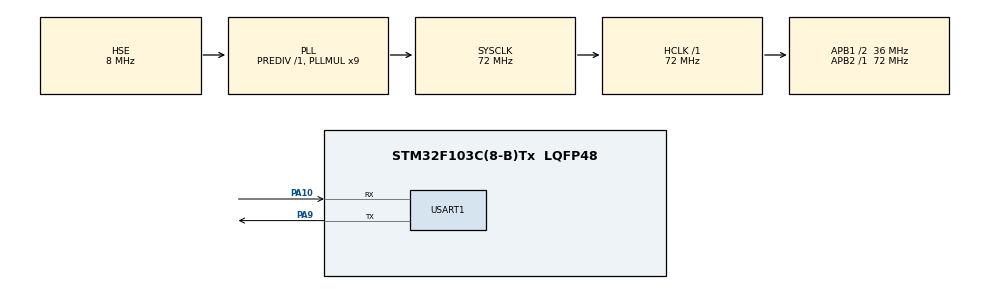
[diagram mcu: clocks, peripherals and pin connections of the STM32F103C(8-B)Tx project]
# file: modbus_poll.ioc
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FREERTOS.INCLUDE_xEventGroupSetBitFromISR=1
FREERTOS.INCLUDE_xTimerPendFunctionCall=1
FREERTOS.Tasks01=defaultTask,0,128,StartDefaultTask,Default,NULL
FREERTOS.configCHECK_FOR_STACK_OVERFLOW=2
FREERTOS.configTIMER_TASK_PRIORITY=3
FREERTOS.configTOTAL_HEAP_SIZE=10240
FREERTOS.configUSE_MALLOC_FAILED_HOOK=1
FREERTOS.configUSE_TIMERS=1
Mcu.Family=STM32F1
Mcu.Name=STM32F103C(8-B)Tx
Mcu.Package=LQFP48
NVIC.PriorityGroup=NVIC_PRIORITYGROUP_4
NVIC.USART1_IRQn=true\:5\:0\:false\:false\:true\:true\:true
PA10.Mode=Asynchronous
PA10.Signal=USART1_RX
PA13.Mode=Serial_Wire
PA13.Signal=SYS_JTMS-SWDIO
PA14.Mode=Serial_Wire
PA14.Signal=SYS_JTCK-SWCLK
PA9.Mode=Asynchronous
PA9.Signal=USART1_TX
PD0-OSC_IN.Mode=HSE-External-Oscillator
PD0-OSC_IN.Signal=RCC_OSC_IN
PD1-OSC_OUT.Mode=HSE-External-Oscillator
PD1-OSC_OUT.Signal=RCC_OSC_OUT
ProjectManager.HeapSize=0x00
ProjectManager.StackSize=0x200
ProjectManager.TargetToolchain=EWARM
RCC.AHBFreq_Value=72000000
RCC.APB1CLKDivider=RCC_HCLK_DIV2
RCC.APB1Freq_Value=36000000
RCC.APB1TimFreq_Value=72000000
RCC.APB2Freq_Value=72000000
RCC.APB2TimFreq_Value=72000000
RCC.HCLKFreq_Value=72000000
RCC.PLLMUL=RCC_PLL_MUL9
RCC.PLLSourceVirtual=RCC_PLLSOURCE_HSE
RCC.SYSCLKFreq_VALUE=72000000
RCC.SYSCLKSource=RCC_SYSCLKSOURCE_PLLCLK
RCC.USBFreq_Value=72000000
USART1.VirtualMode=VM_ASYNC
VP_FREERTOS_VS_ENABLE.Mode=Enabled
board=modbus_poll

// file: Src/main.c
/**
  ******************************************************************************
  * File Name          : main.c
  * Description        : Main program body
  ******************************************************************************
  * This notice applies to any and all portions of this file
  * that are not between comment pairs USER CODE BEGIN and
  * USER CODE END. Other portions of this file, whether
  * inserted by the user or by software development tools
  * are owned by their respective copyright owners.
  *
  * Copyright (c) 2018 STMicroelectronics International N.V.
  * All rights reserved.
  *
  * Redistribution and use in source and binary forms, with or without
  * modification, are permitted, provided that the following conditions are met:
  *
  * 1. Redistribution of source code must retain the above copyright notice,
  *    this list of conditions and the following disclaimer.
  * 2. Redistributions in binary form must reproduce the above copyright notice,
  *    this list of conditions and the following disclaimer in the documentation
  *    and/or other materials provided with the distribution.
  * 3. Neither the name of STMicroelectronics nor the names of other
  *    contributors to this software may be used to endorse or promote products
  *    derived from this software without specific written permission.
  * 4. This software, including modifications and/or derivative works of this
  *    software, must execute solely and exclusively on microcontroller or
  *    microprocessor devices manufactured by or for STMicroelectronics.
  * 5. Redistribution and use of this software other than as permitted under
  *    this license is void and will automatically terminate your rights under
  *    this license.
  *
  * THIS SOFTWARE IS PROVIDED BY STMICROELECTRONICS AND CONTRIBUTORS "AS IS"
  * AND ANY EXPRESS, IMPLIED OR STATUTORY WARRANTIES, INCLUDING, BUT NOT
  * LIMITED TO, THE IMPLIED WARRANTIES OF MERCHANTABILITY, FITNESS FOR A
  * PARTICULAR PURPOSE AND NON-INFRINGEMENT OF THIRD PARTY INTELLECTUAL PROPERTY
  * RIGHTS ARE DISCLAIMED TO THE FULLEST EXTENT PERMITTED BY LAW. IN NO EVENT
  * SHALL STMICROELECTRONICS OR CONTRIBUTORS BE LIABLE FOR ANY DIRECT, INDIRECT,
  * INCIDENTAL, SPECIAL, EXEMPLARY, OR CONSEQUENTIAL DAMAGES (INCLUDING, BUT NOT
  * LIMITED TO, PROCUREMENT OF SUBSTITUTE GOODS OR SERVICES; LOSS OF USE, DATA,
  * OR PROFITS; OR BUSINESS INTERRUPTION) HOWEVER CAUSED AND ON ANY THEORY OF
  * LIABILITY, WHETHER IN CONTRACT, STRICT LIABILITY, OR TORT (INCLUDING
  * NEGLIGENCE OR OTHERWISE) ARISING IN ANY WAY OUT OF THE USE OF THIS SOFTWARE,
  * EVEN IF ADVISED OF THE POSSIBILITY OF SUCH DAMAGE.
  *
  ******************************************************************************
  */

#include "main.h"
#include "stm32f1xx_hal.h"
#include "cmsis_os.h"
#include "usart.h"
#include "gpio.h"

/* USER CODE BEGIN PV */
/* Private variables ---------------------------------------------------------*/

/* USER CODE END PV */

void SystemClock_Config(void);
void MX_FREERTOS_Init(void);

/* USER CODE BEGIN PFP */
/* Private function prototypes -----------------------------------------------*/

/* USER CODE END PFP */

int main(void)
{

  /* MCU Configuration----------------------------------------------------------*/

  /* Reset of all peripherals, Initializes the Flash interface and the Systick. */
  HAL_Init();

  /* Configure the system clock */
  SystemClock_Config();

  /* Initialize all configured peripherals */
  MX_GPIO_Init();
  MX_USART1_UART_Init();

  /* Call init function for freertos objects (in freertos.c) */
  MX_FREERTOS_Init();

  /* Start scheduler */
  osKernelStart();

  /* We should never get here as control is now taken by the scheduler */

  /* Infinite loop */
  while (1)
  {

  }

}

/** System Clock Configuration
*/
void SystemClock_Config(void)
{

  RCC_OscInitTypeDef RCC_OscInitStruct;
  RCC_ClkInitTypeDef RCC_ClkInitStruct;

    /**Initializes the CPU, AHB and APB busses clocks
    */
  RCC_OscInitStruct.OscillatorType = RCC_OSCILLATORTYPE_HSE;
  RCC_OscInitStruct.HSEState = RCC_HSE_ON;
  RCC_OscInitStruct.HSEPredivValue = RCC_HSE_PREDIV_DIV1;
  RCC_OscInitStruct.HSIState = RCC_HSI_ON;
  RCC_OscInitStruct.PLL.PLLState = RCC_PLL_ON;
  RCC_OscInitStruct.PLL.PLLSource = RCC_PLLSOURCE_HSE;
  RCC_OscInitStruct.PLL.PLLMUL = RCC_PLL_MUL9;
  if (HAL_RCC_OscConfig(&RCC_OscInitStruct) != HAL_OK)
  {
    _Error_Handler(__FILE__, __LINE__);
  }

    /**Initializes the CPU, AHB and APB busses clocks
    */
  RCC_ClkInitStruct.ClockType = RCC_CLOCKTYPE_HCLK|RCC_CLOCKTYPE_SYSCLK
                              |RCC_CLOCKTYPE_PCLK1|RCC_CLOCKTYPE_PCLK2;
  RCC_ClkInitStruct.SYSCLKSource = RCC_SYSCLKSOURCE_PLLCLK;
  RCC_ClkInitStruct.AHBCLKDivider = RCC_SYSCLK_DIV1;
  RCC_ClkInitStruct.APB1CLKDivider = RCC_HCLK_DIV2;
  RCC_ClkInitStruct.APB2CLKDivider = RCC_HCLK_DIV1;

  if (HAL_RCC_ClockConfig(&RCC_ClkInitStruct, FLASH_LATENCY_2) != HAL_OK)
  {
    _Error_Handler(__FILE__, __LINE__);
  }

    /**Configure the Systick interrupt time
    */
  HAL_SYSTICK_Config(HAL_RCC_GetHCLKFreq()/1000);

    /**Configure the Systick
    */
  HAL_SYSTICK_CLKSourceConfig(SYSTICK_CLKSOURCE_HCLK);

  /* SysTick_IRQn interrupt configuration */
  HAL_NVIC_SetPriority(SysTick_IRQn, 15, 0);
}

void _Error_Handler(char * file, int line)
{
  while(1)
  {
  }
}

/************************ (C) COPYRIGHT STMicroelectronics *****END OF FILE****/

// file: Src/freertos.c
/**
  ******************************************************************************
  * File Name          : freertos.c
  * Description        : Code for freertos applications
  ******************************************************************************
  * This notice applies to any and all portions of this file
  * that are not between comment pairs USER CODE BEGIN and
  * USER CODE END. Other portions of this file, whether
  * inserted by the user or by software development tools
  * are owned by their respective copyright owners.
  *
  * Copyright (c) 2018 STMicroelectronics International N.V.
  * All rights reserved.
  *
  * Redistribution and use in source and binary forms, with or without
  * modification, are permitted, provided that the following conditions are met:
  *
  * 1. Redistribution of source code must retain the above copyright notice,
  *    this list of conditions and the following disclaimer.
  * 2. Redistributions in binary form must reproduce the above copyright notice,
  *    this list of conditions and the following disclaimer in the documentation
  *    and/or other materials provided with the distribution.
  * 3. Neither the name of STMicroelectronics nor the names of other
  *    contributors to this software may be used to endorse or promote products
  *    derived from this software without specific written permission.
  * 4. This software, including modifications and/or derivative works of this
  *    software, must execute solely and exclusively on microcontroller or
  *    microprocessor devices manufactured by or for STMicroelectronics.
  * 5. Redistribution and use of this software other than as permitted under
  *    this license is void and will automatically terminate your rights under
  *    this license.
  *
  * THIS SOFTWARE IS PROVIDED BY STMICROELECTRONICS AND CONTRIBUTORS "AS IS"
  * AND ANY EXPRESS, IMPLIED OR STATUTORY WARRANTIES, INCLUDING, BUT NOT
  * LIMITED TO, THE IMPLIED WARRANTIES OF MERCHANTABILITY, FITNESS FOR A
  * PARTICULAR PURPOSE AND NON-INFRINGEMENT OF THIRD PARTY INTELLECTUAL PROPERTY
  * RIGHTS ARE DISCLAIMED TO THE FULLEST EXTENT PERMITTED BY LAW. IN NO EVENT
  * SHALL STMICROELECTRONICS OR CONTRIBUTORS BE LIABLE FOR ANY DIRECT, INDIRECT,
  * INCIDENTAL, SPECIAL, EXEMPLARY, OR CONSEQUENTIAL DAMAGES (INCLUDING, BUT NOT
  * LIMITED TO, PROCUREMENT OF SUBSTITUTE GOODS OR SERVICES; LOSS OF USE, DATA,
  * OR PROFITS; OR BUSINESS INTERRUPTION) HOWEVER CAUSED AND ON ANY THEORY OF
  * LIABILITY, WHETHER IN CONTRACT, STRICT LIABILITY, OR TORT (INCLUDING
  * NEGLIGENCE OR OTHERWISE) ARISING IN ANY WAY OUT OF THE USE OF THIS SOFTWARE,
  * EVEN IF ADVISED OF THE POSSIBILITY OF SUCH DAMAGE.
  *
  ******************************************************************************
  */

#include "FreeRTOS.h"
#include "task.h"
#include "cmsis_os.h"

/* USER CODE BEGIN Includes */
#include "modbus_poll.h"
#define APP_LOG_MODULE_NAME   "[task]"
#define APP_LOG_MODULE_LEVEL   APP_LOG_LEVEL_DEBUG
#include "app_log.h"
/* USER CODE END Includes */

osThreadId defaultTaskHandle;
osThreadId read_weight_task_hdl;

void StartDefaultTask(void const * argument);
void read_weight_task(void const * argument);
void MX_FREERTOS_Init(void); /* (MISRA C 2004 rule 8.1) */

/* Hook prototypes */
void vApplicationStackOverflowHook(xTaskHandle xTask, signed char *pcTaskName);
void vApplicationMallocFailedHook(void);

/* USER CODE BEGIN 4 */
__weak void vApplicationStackOverflowHook(xTaskHandle xTask, signed char *pcTaskName)
{
   /* Run time stack overflow checking is performed if
   configCHECK_FOR_STACK_OVERFLOW is defined to 1 or 2. This hook function is
   called if a stack overflow is detected. */
}
/* USER CODE END 4 */

/* USER CODE BEGIN 5 */
__weak void vApplicationMallocFailedHook(void)
{
   /* vApplicationMallocFailedHook() will only be called if
   configUSE_MALLOC_FAILED_HOOK is set to 1 in FreeRTOSConfig.h. It is a hook
   function that will get called if a call to pvPortMalloc() fails.
   pvPortMalloc() is called internally by the kernel whenever a task, queue,
   timer or semaphore is created. It is also called by various parts of the
   demo application. If heap_1.c or heap_2.c are used, then the size of the
   heap available to pvPortMalloc() is defined by configTOTAL_HEAP_SIZE in
   FreeRTOSConfig.h, and the xPortGetFreeHeapSize() API function can be used
   to query the size of free heap space that remains (although it does not
   provide information on how the remaining heap might be fragmented). */
}
/* USER CODE END 5 */

/* Init FreeRTOS */

void MX_FREERTOS_Init(void) {

  /* Create the thread(s) */
  /* definition and creation of defaultTask */
  osThreadDef(defaultTask, StartDefaultTask, osPriorityNormal, 0, 128);
  defaultTaskHandle = osThreadCreate(osThread(defaultTask), NULL);

  /* USER CODE BEGIN RTOS_THREADS */
  /* add threads, ... */
  osThreadDef(read_weight_task, read_weight_task, osPriorityNormal, 0, 256);
  read_weight_task_hdl = osThreadCreate(osThread(read_weight_task), NULL);

  /* USER CODE END RTOS_THREADS */

}

/* StartDefaultTask function */
void StartDefaultTask(void const * argument)
{

  /* USER CODE BEGIN StartDefaultTask */
  uint16_t reg[10];
  mb_poll_status_t status;
  modbus_poll_init();
  modbus_poll_pre_transmission(0);
  modbus_poll_post_transmission(0);
  /* Infinite loop */
  for(;;)
  {
    /*功能码0x01 读取线圈状态*/
    status= modbus_poll_readCoils(1,10,17,reg);
    if(status!=MODBUS_POLL_STATUS_SUCCESS)
    {
     APP_LOG_ERROR("读线圈错误！\r\n");
    }
    else
    {
    APP_LOG_DEBUG("读线圈值：%d.%d.\r\n",reg[0],reg[1]);
    }
   osDelay(1);
   /*功能码0x0F 写多个线圈*/
   reg[0]=0x5555;
   reg[1]=0xaaaa;
   status= modbus_poll_write_multiple_coils(2,10,17,reg);

   if(status!=MODBUS_POLL_STATUS_SUCCESS)
   {
    APP_LOG_ERROR("写多个线圈错误！\r\n");
   }
     osDelay(1);
    status=modbus_poll_read_input_registers(1,20,10,reg);

    if(status!=MODBUS_POLL_STATUS_SUCCESS)
    {
     APP_LOG_ERROR("读输入寄存器错误！\r\n");
    }
    else
    {
    for(uint8_t i=0;i<10;i++)
    {
    // APP_LOG_DEBUG("读取的输入寄存器值:%d.\r\n",reg[i]);
    }
    }
    osDelay(1);
    status= modbus_poll_write_single_coil(1,10,0);
    if(status!=MODBUS_POLL_STATUS_SUCCESS)
    {
     APP_LOG_ERROR("写单个线圈错误！\r\n");
    }
    osDelay(1);
   /*功能码0x10*/
    status= modbus_poll_write_multiple_registers(1,0,10, reg);
    if(status!=MODBUS_POLL_STATUS_SUCCESS)
    {
     APP_LOG_ERROR("写多个寄存器错误！\r\n");
    }
     osDelay(1);
  }
  /* USER CODE END StartDefaultTask */
}

/* USER CODE BEGIN Application */

void read_weight_task(void const * argument)
{
  uint16_t reg[4];
  mb_poll_status_t status;
  osDelay(1000);
  /* Infinite loop */
  for(;;)
  {
    /*功能码0x03 读保持寄存器*/
  status= modbus_poll_read_holding_registers(2,0,4,reg);
  if(status!=MODBUS_POLL_STATUS_SUCCESS)
  {
   APP_LOG_ERROR("读净重错误！\r\n");
  }
  else
  {
  APP_LOG_DEBUG("读净重值：1.%2x 2.%2x 3.%2x 4.%2x\r\n",reg[0],reg[1],reg[2],reg[3]);
  }
  osDelay(1);
  }
}
/* USER CODE END Application */

/************************ (C) COPYRIGHT STMicroelectronics *****END OF FILE****/
